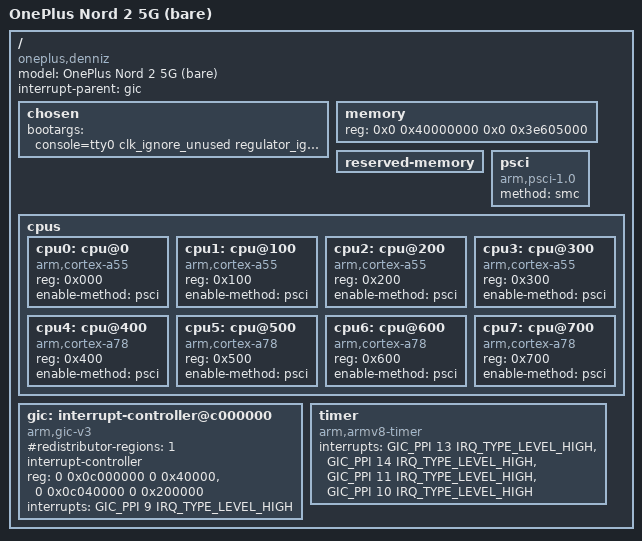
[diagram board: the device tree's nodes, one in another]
// SPDX-License-Identifier: (GPL-2.0 OR MIT)
/*
 * Bring-up bisection tree: only CPUs, PSCI, the GIC and the timer, without
 * mt6893.dtsi. The GIC uses 3 interrupt cells and no PPI partitions, as in
 * the stock tree.
 */

/dts-v1/;

#include <dt-bindings/interrupt-controller/arm-gic.h>
#include <dt-bindings/interrupt-controller/irq.h>

/ {
	model = "OnePlus Nord 2 5G (bare)";
	compatible = "oneplus,denniz", "mediatek,mt6893";
	interrupt-parent = <&gic>;
	#address-cells = <2>;
	#size-cells = <2>;

	chosen {
		bootargs = "console=tty0 clk_ignore_unused regulator_ignore_unused pd_ignore_unused ignore_loglevel panic=1 ramoops.mem_address=0x48090000 ramoops.mem_size=0xe0000 ramoops.console_size=0x40000 ramoops.pmsg_size=0x10000";
	};

	memory {
		device_type = "memory";
		reg = <0x0 0x40000000 0x0 0x3e605000>;
	};

	reserved-memory {
		#address-cells = <2>;
		#size-cells = <2>;
		ranges;
	};

	psci {
		compatible = "arm,psci-1.0";
		method = "smc";
	};

	cpus {
		#address-cells = <1>;
		#size-cells = <0>;

		cpu0: cpu@0   { device_type = "cpu"; compatible = "arm,cortex-a55"; reg = <0x000>; enable-method = "psci"; };
		cpu1: cpu@100 { device_type = "cpu"; compatible = "arm,cortex-a55"; reg = <0x100>; enable-method = "psci"; };
		cpu2: cpu@200 { device_type = "cpu"; compatible = "arm,cortex-a55"; reg = <0x200>; enable-method = "psci"; };
		cpu3: cpu@300 { device_type = "cpu"; compatible = "arm,cortex-a55"; reg = <0x300>; enable-method = "psci"; };
		cpu4: cpu@400 { device_type = "cpu"; compatible = "arm,cortex-a78"; reg = <0x400>; enable-method = "psci"; };
		cpu5: cpu@500 { device_type = "cpu"; compatible = "arm,cortex-a78"; reg = <0x500>; enable-method = "psci"; };
		cpu6: cpu@600 { device_type = "cpu"; compatible = "arm,cortex-a78"; reg = <0x600>; enable-method = "psci"; };
		cpu7: cpu@700 { device_type = "cpu"; compatible = "arm,cortex-a78"; reg = <0x700>; enable-method = "psci"; };
	};

	gic: interrupt-controller@c000000 {
		compatible = "arm,gic-v3";
		#interrupt-cells = <3>;
		#redistributor-regions = <1>;
		interrupt-controller;
		reg = <0 0x0c000000 0 0x40000>,
		      <0 0x0c040000 0 0x200000>;
		interrupts = <GIC_PPI 9 IRQ_TYPE_LEVEL_HIGH>;
	};

	timer {
		compatible = "arm,armv8-timer";
		interrupts = <GIC_PPI 13 IRQ_TYPE_LEVEL_HIGH>,
			     <GIC_PPI 14 IRQ_TYPE_LEVEL_HIGH>,
			     <GIC_PPI 11 IRQ_TYPE_LEVEL_HIGH>,
			     <GIC_PPI 10 IRQ_TYPE_LEVEL_HIGH>;
	};
};
